# STM32H7S register map
File version: 1.3
CPU: CM7 r0p1, little endian, MPU, FPU, 4 interrupt priority bits
Registers are 32-bit, read-write, reset 0x0 unless marked. A register's access mark holds for its fields unless they carry their own. Offsets are from the block's base; [hi:lo] are bit positions; lines under a group give offsets from that group; {n}, {i} and the like mark numbered series.

## CRYP — Cryptographic processor
Base 0x48020800
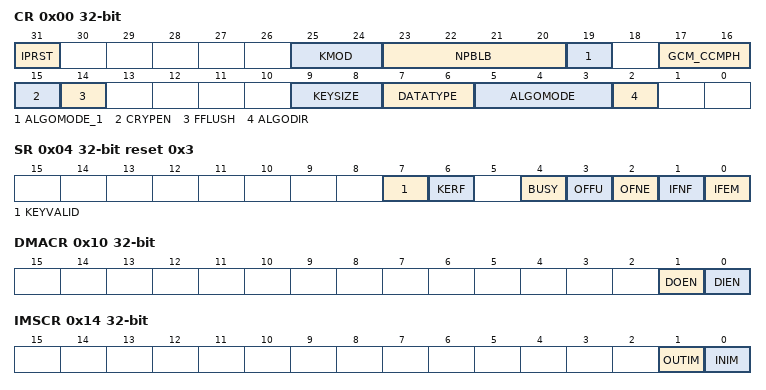
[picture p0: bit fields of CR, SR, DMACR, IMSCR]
0x00 CR — CRYP control register
  [31] IPRST — CRYP peripheral software reset Setting the bit resets the CRYP peripheral, putting all registers to their default values, except the IPRST bit itself. This bit must be kept cleared while writing any configuration registers.
  [25:24] KMOD — Key mode selection This bitfield defines how the CRYP key can be used by the application. KEYSIZE must be correctly initialized when setting KMOD[1:0] different from zero. Others: Reserved Attempts to write the bitfield are ignored when BUSY is set.
  [23:20] NPBLB — Number of padding bytes in last block This padding information must be filled by software before processing the last block of GCM payload encryption or CCM payload decryption, otherwise authentication tag computation is incorrect. ... Attempts to write the bitfield are ignored when BUSY is set.
  [19] ALGOMODE_1 — ALGOMODE[3]
  [17:16] GCM_CCMPH — GCM or CCM phase selection This bitfield selects the phase, applicable only with GCM, GMAC or CCM chaining modes. Attempts to write the bitfield are ignored when BUSY is set.
  [15] CRYPEN — CRYP enable This bit enables/disables the CRYP peripheral. This bit is automatically cleared by hardware upon the completion of the key preparation (ALGOMODE[3:0] at 0x7) and upon the completion of GCM/GMAC/CCM initialization phase. The bit cannot be set as long as KEYVALID is cleared.
  [14] FFLUSH — FIFO flush This bit enables/disables the flushing of CRYP input and output FIFOs. Reading this bit always returns 0. When CRYPEN is cleared, writing this bit to 1 flushes both input and output FIFOs (that is read and write pointers of the FIFOs are reset). FFLUSH bit must be set when BUSY is cleared, otherwise the FIFO is flushed, but the block being processed may be pushed into the output FIFO just after the flush operation, resulting in a non-empty FIFO condition. Attempts to write FFLUSH are ignored when CRYPEN is set.
  [9:8] KEYSIZE — Key size selection This bitfield defines the key length in bits of the key used by CRYP. When KEYSIZE is changed, KEYVALID bit is cleared. Attempts to write the bitfield are ignored when BUSY is set.
  [7:6] DATATYPE — Data type This bitfield defines the format of data written in the CRYP_DINR register or read from the CRYP_DOUTR register, through selecting the mode of data swapping. This swapping is defined in Section 60.4.15: CRYP data registers and data swapping. Attempts to write the bitfield are ignored when BUSY is set.
  [5:3] ALGOMODE — ALGOMODE[2:0]: Algorithm mode This bitfield selects the AES algorithm/chaining mode. Others: Reserved Attempts to write the bitfield are ignored when BUSY is set.
  [2] ALGODIR — Algorithm direction This bit selects the algorithm direction. Attempts to write the bitfield are ignored when BUSY is set.
0x04 SR ro reset 0x3 — CRYP status register
  [7] KEYVALID — Key valid flag This read-only bit is set by hardware when the key of size defined by KEYSIZE is loaded in CRYP_KxR/LR key registers. The CRYPEN bit can only be set when KEYVALID is set. In normal mode when KMOD[1:0] is at zero, the key must be written in the key registers in the correct sequence, otherwise the KERF flag is set and KEYVALID remains cleared. When KMOD[1:0] is different from zero, the BUSY flag is automatically set by CRYP. When the key is loaded successfully, BUSY is cleared and KEYVALID set. Upon an error, KERF is set, BUSY cleared and KEYVALID remains cleared. If set, KERF must be cleared, otherwise KEYVALID cannot be set. For further information on key loading, refer to Section 60.4.16: CRYP key registers.
  [6] KERF — Key error flag This read-only bit is set by hardware when key information failed to load into key registers. KERF is triggered upon any of the following errors: CRYP_KxR/LR register write does not respect the correct order (refer to Section 60.4.16: CRYP key registers for details). CRYP fails to load the key shared by SAES peripheral (KMOD = 0x2). KERF must be cleared by the application software, otherwise KEYVALID cannot be set. It can be done through IPRST bit of CRYP_CR, or when a correct key writing sequence starts.
  [4] BUSY — Busy bit This flag indicates whether CRYP is idle or busy. CRYP is flagged as idle when disabled (CRYPEN = 0) or when the AES core is not processing any data. It happens when the last processing has completed, or CRYP is waiting for enough data in the input FIFO or enough free space in the output FIFO (that is in each case at least 4 words). CRYP is flagged as busy when processing a block data, preparing a key (ECB or CBC decryption only), or transferring a shared key from SAES peripheral.
  [3] OFFU — Output FIFO full flag
  [2] OFNE — Output FIFO not empty flag
  [1] IFNF — Input FIFO not full flag
  [0] IFEM — Input FIFO empty flag
0x08 DINR — CRYP data input register
  [31:0] DIN — Data input A four-fold sequential write to this bitfield during the Input phase results in pushing a complete 16-byte block into the CRYP input FIFO. From the first to the fourth write, the corresponding data weights are [127:96], [95:64], [63:32], and [31:0]. Input FIFO can receive up to two 16-byte blocks of plaintext (when encrypting) or ciphertext (when decrypting). If EN bit is set in CRYP_CR register, when at least four 32-bit words have been pushed into the input FIFO, and when at least four 32-bit words are free in the output FIFO, the CRYP automatically starts an encryption or decryption process, setting the BUSY bit. Reading this register pops data off the input FIFO (oldest value is returned). The data present in the input FIFO are returned only if CRYPEN is cleared (undefined value is returned otherwise). Following one or more reads the FIFO must be flushed (setting the FFLUSH bit) prior to processing new data.
0x0C DOUTR ro — CRYP data output register
  [31:0] DOUT — Data output A four-fold sequential read to this bitfield during the output phase results in retrieving a complete 16-byte block from the CRYP output FIFO. From the first to the fourth read, the corresponding data weights are [127:96], [95:64], [63:32], and [31:0]. Output FIFO can store up to two 16-byte blocks of plaintext (when decrypting) or ciphertext (when encrypting). When the output FIFO is empty a read returns an undefined value. Writes are ignored.
0x10 DMACR — CRYP DMA control register
  [1] DOEN — DMA output enable When this bit is set, DMA requests are automatically generated by the peripheral during the output data phase.
  [0] DIEN — DMA input enable When this bit is set, DMA requests are automatically generated by the peripheral during the input data phase.
0x14 IMSCR — CRYP interrupt mask set/clear register
  [1] OUTIM — Output FIFO service interrupt mask This bit enables or disables (masks) the CRYP output FIFO service interrupt generation when OUTRIS is set.
  [0] INIM — Input FIFO service interrupt mask This bit enables or disables (masks) the CRYP input FIFO service interrupt generation when INRIS is set.
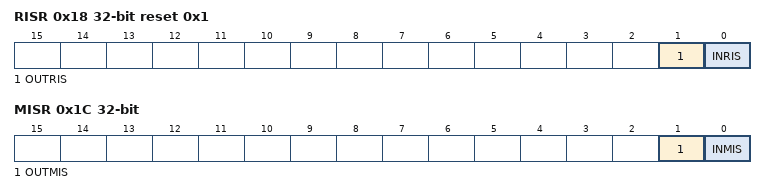
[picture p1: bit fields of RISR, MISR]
0x18 RISR ro reset 0x1 — CRYP raw interrupt status register
  [1] OUTRIS — Output FIFO service raw interrupt status This read-only bit is set by hardware when an output FIFO flag (OFFU or OFNE) is set in CRYP_SR register, regardless of the OUTIM mask bit value in CRYP_IMSCR register.
  [0] INRIS — Input FIFO service raw interrupt status This read-only bit is set by hardware when an input FIFO flag (IFNF or IFEM) is set in CRYP_SR register, regardless of the INIM mask bit value in CRYP_IMSCR register.
0x1C MISR ro — CRYP masked interrupt status register
  [1] OUTMIS — Output FIFO service masked interrupt status This read-only bit is set by hardware when an output FIFO flag (OFFU or OFNE) is set in CRYP_SR register. If the OUTIM mask bit is cleared in CRYP_IMSCR register, the OUTMIS bit stays cleared (masked). The OUTMIS bit is cleared by reading data from the output FIFO until OFNE flag is cleared (output FIFO empty). It is not cleared by disabling CRYP with CRYPEN bit.
  [0] INMIS — Input FIFO service masked interrupt status This read-only bit is set by hardware when an input FIFO flag (IFNF or IFEM) is set in CRYP_SR register. If the INIM mask bit is cleared in CRYP_IMSCR register, the INMIS bit stays cleared (masked). The INMIS bit is cleared by writing data to the input FIFO until IFEM flag is cleared (there is at least one word in input FIFO), or by clearing CRYPEN, When CRYP is disabled, INMIS bit stays low even if the input FIFO is empty.
{0x20+8i} KEY{i} (i=0..3) group — Cluster KEY{i}, containing K?LR, K?RR
  0x00 KLR wo — CRYP key register 0L
    [31:0] K — Key bit x This write-only bitfield contains the bits [255:224] of the AES encryption or decryption key, depending on the operating mode. Write to CRYP_KxR/LR registers is ignored when CRYP is busy (BUSY bit set). When key is coming from the SAES peripheral (KMOD[1:0] = 0x2), write is also ignored. With KMOD[1:0] at 0x0, a special writing sequence is required. In this sequence, any valid write to CRYP_KxR/LR register clears the KEYVALID flag except for the sequence-completing write that sets it. Also refer to the description of the KEYVALID flag in the CRYP_SR register.
  0x04 KRR wo — CRYP key register 0R
    [31:0] K — Key bit x This write-only bitfield contains the bits [223:192] of the AES encryption or decryption key, depending on the operating mode. Refer to the CRYP_K0LR register for information relative to writing CRYP_KxR/LR registers.
{0x40+8i} INIT{i} (i=0..1) group — Cluster INIT{i}, containing IV?LR, IV?RR
  0x00 IVLR — CRYP initialization vector register 0L
    [31:0] IVI — Initialization vector bit x This bitfield stores the initialization vector bits [127:96] for AES chaining modes other than ECB. The value stored in CRYP_IVxR/LR registers is updated by hardware after each computation round (when applicable). Write to this register is ignored when CRYP is busy (BUSY bit set).
  0x04 IVRR — CRYP initialization vector register 0R
    [31:0] IVI — Initialization vector bit x This bitfield stores the initialization vector bits [95:64] for AES chaining modes other than ECB. The value stored in CRYP_IVxR/LR registers is updated by hardware after each computation round (when applicable). Write to this register is ignored when CRYP is busy (BUSY bit set).
{0x50+4i} CSGCMCCM{i}R (i=0..7) — CRYP context swap GCM-CCM registers
  [31:0] CSGCMCCM — Context swap for GCM/GMAC and CCM modes CRYP_CSGCMCCMxR registers contain the complete internal register states of the CRYP when the GCM, GMAC or CCM processing of the current task is suspended to process a higher-priority task. Refer to Section 60.4.8: CRYP suspend and resume operations for more details. CRYP_CSGCMCCMxR registers are not used in other chaining modes than GCM, GMAC or CCM.
{0x70+4i} CSGCM{i}R (i=0..7) — CRYP context swap GCM registers
  [31:0] CSGCM — Context swap for GCM/GMAC modes CRYP_CSGCMxR registers contain the complete internal register states of the CRYP when the GCM or GMAC processing of the current task is suspended to process a higher-priority task. Refer to Section 60.4.8: CRYP suspend and resume operations for more details. CRYP_CSGCMxR registers are not used in other chaining modes than GCM or GMAC.
